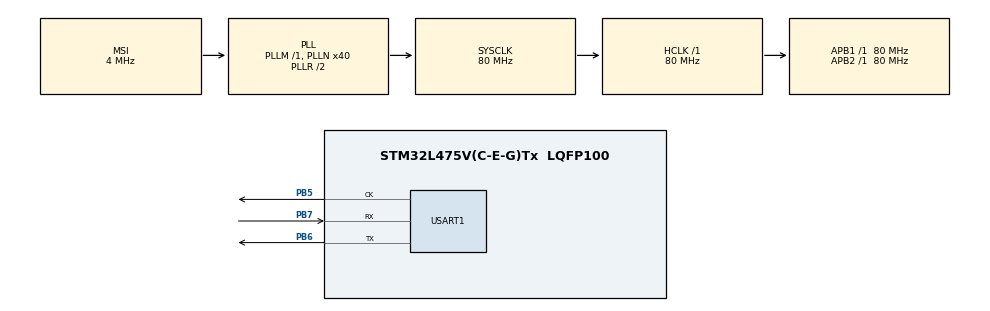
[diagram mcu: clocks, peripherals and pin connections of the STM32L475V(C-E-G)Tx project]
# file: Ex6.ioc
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Mcu.Family=STM32L4
Mcu.Name=STM32L475V(C-E-G)Tx
Mcu.Package=LQFP100
NVIC.PriorityGroup=NVIC_PRIORITYGROUP_4
PB5.Mode=Synchronous
PB5.Signal=USART1_CK
PB6.Mode=Synchronous
PB6.Signal=USART1_TX
PB7.Mode=Synchronous
PB7.Signal=USART1_RX
ProjectManager.HeapSize=0x200
ProjectManager.StackSize=0x400
ProjectManager.TargetToolchain=STM32CubeIDE
RCC.ADCFreq_Value=48000000
RCC.AHBFreq_Value=80000000
RCC.APB1Freq_Value=80000000
RCC.APB1TimFreq_Value=80000000
RCC.APB2Freq_Value=80000000
RCC.APB2TimFreq_Value=80000000
RCC.CortexFreq_Value=80000000
RCC.HCLKFreq_Value=80000000
RCC.HSE_VALUE=8000000
RCC.HSI_VALUE=16000000
RCC.LSE_VALUE=32768
RCC.MSI_VALUE=4000000
RCC.PLLN=40
RCC.PLLSAI1N=24
RCC.SYSCLKFreq_VALUE=80000000
RCC.SYSCLKSource=RCC_SYSCLKSOURCE_PLLCLK
RCC.USBFreq_Value=48000000
RCC.VCOOutputFreq_Value=160000000
USART1.VirtualMode-Synchronous=VM_SYNC
board=B-L475E-IOT01A2

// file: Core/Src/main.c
/* USER CODE BEGIN Header */
/**
  ******************************************************************************
  * @file           : main.c
  * @brief          : Main program body
  ******************************************************************************
  * @attention
  *
  * Copyright (c) 2024 STMicroelectronics.
  * All rights reserved.
  *
  * This software is licensed under terms that can be found in the LICENSE file
  * in the root directory of this software component.
  * If no LICENSE file comes with this software, it is provided AS-IS.
  *
  ******************************************************************************
  */
/* USER CODE END Header */
#include "main.h"
#include "usart.h"
#include "gpio.h"

/* USER CODE BEGIN Includes */
#include "stdio.h"
#include "app.h"

/* USER CODE END Includes */

void SystemClock_Config(void);
/* USER CODE BEGIN PFP */
__attribute__((weak)) int _write(int file, char* ptr, int len)
{
	HAL_USART_Transmit(&husart1, (uint8_t*)ptr, len, HAL_MAX_DELAY);
	return len;
}

#ifdef __GNUC__
/* With GCC/RAISONANCE, small msg_info (option LD Linker->Libraries->Small msg_info
   set to 'Yes') calls __io_putchar() */
#define PUTCHAR_PROTOTYPE int __io_putchar(int ch)
#define GETCHAR_PROTOTYPE int __io_getchar(void)
#else
#define PUTCHAR_PROTOTYPE int fputc(int ch, FILE *f)
#define GETCHAR_PROTOTYPE int fgetc(FILE *f)
#endif /* __GNUC__ */

PUTCHAR_PROTOTYPE
{
  /* Place your implementation of fputc here */
  /* e.g. write a character to the serial port and Loop until the end of transmission */
  while (HAL_OK != HAL_USART_Transmit(&husart1, (uint8_t *) &ch, 1, 30000))
  {
    ;
  }
  return ch;
}

/**
  * @brief Retargets the C library scanf function to the USART.
  * @param None
  * @retval None
  */
GETCHAR_PROTOTYPE
{
  /* Place your implementation of fgetc here */
  /* e.g. readwrite a character to the USART2 and Loop until the end of transmission */
  uint8_t ch = 0;
  while (HAL_OK != HAL_USART_Receive(&husart1, (uint8_t *)&ch, 1, 30000))
  {
    ;
  }
  return ch;
}

/* USER CODE END PFP */

int main(void)
{

  /* MCU Configuration--------------------------------------------------------*/

  /* Reset of all peripherals, Initializes the Flash interface and the Systick. */
  HAL_Init();

  /* Configure the system clock */
  SystemClock_Config();

  /* Initialize all configured peripherals */
  MX_GPIO_Init();
  MX_USART1_Init();
  /* USER CODE BEGIN 2 */
  printf("Inference started");
  application();
  /* USER CODE END 2 */

  /* Infinite loop */

}

void SystemClock_Config(void)
{
  RCC_OscInitTypeDef RCC_OscInitStruct = {0};
  RCC_ClkInitTypeDef RCC_ClkInitStruct = {0};

  /** Configure the main internal regulator output voltage
  */
  if (HAL_PWREx_ControlVoltageScaling(PWR_REGULATOR_VOLTAGE_SCALE1) != HAL_OK)
  {
    Error_Handler();
  }

  /** Initializes the RCC Oscillators according to the specified parameters
  * in the RCC_OscInitTypeDef structure.
  */
  RCC_OscInitStruct.OscillatorType = RCC_OSCILLATORTYPE_MSI;
  RCC_OscInitStruct.MSIState = RCC_MSI_ON;
  RCC_OscInitStruct.MSICalibrationValue = 0;
  RCC_OscInitStruct.MSIClockRange = RCC_MSIRANGE_6;
  RCC_OscInitStruct.PLL.PLLState = RCC_PLL_ON;
  RCC_OscInitStruct.PLL.PLLSource = RCC_PLLSOURCE_MSI;
  RCC_OscInitStruct.PLL.PLLM = 1;
  RCC_OscInitStruct.PLL.PLLN = 40;
  RCC_OscInitStruct.PLL.PLLP = RCC_PLLP_DIV7;
  RCC_OscInitStruct.PLL.PLLQ = RCC_PLLQ_DIV2;
  RCC_OscInitStruct.PLL.PLLR = RCC_PLLR_DIV2;
  if (HAL_RCC_OscConfig(&RCC_OscInitStruct) != HAL_OK)
  {
    Error_Handler();
  }

  /** Initializes the CPU, AHB and APB buses clocks
  */
  RCC_ClkInitStruct.ClockType = RCC_CLOCKTYPE_HCLK|RCC_CLOCKTYPE_SYSCLK
                              |RCC_CLOCKTYPE_PCLK1|RCC_CLOCKTYPE_PCLK2;
  RCC_ClkInitStruct.SYSCLKSource = RCC_SYSCLKSOURCE_PLLCLK;
  RCC_ClkInitStruct.AHBCLKDivider = RCC_SYSCLK_DIV1;
  RCC_ClkInitStruct.APB1CLKDivider = RCC_HCLK_DIV1;
  RCC_ClkInitStruct.APB2CLKDivider = RCC_HCLK_DIV1;

  if (HAL_RCC_ClockConfig(&RCC_ClkInitStruct, FLASH_LATENCY_4) != HAL_OK)
  {
    Error_Handler();
  }
}

void Error_Handler(void)
{
  __disable_irq();
  while (1)
  {
  }
}
